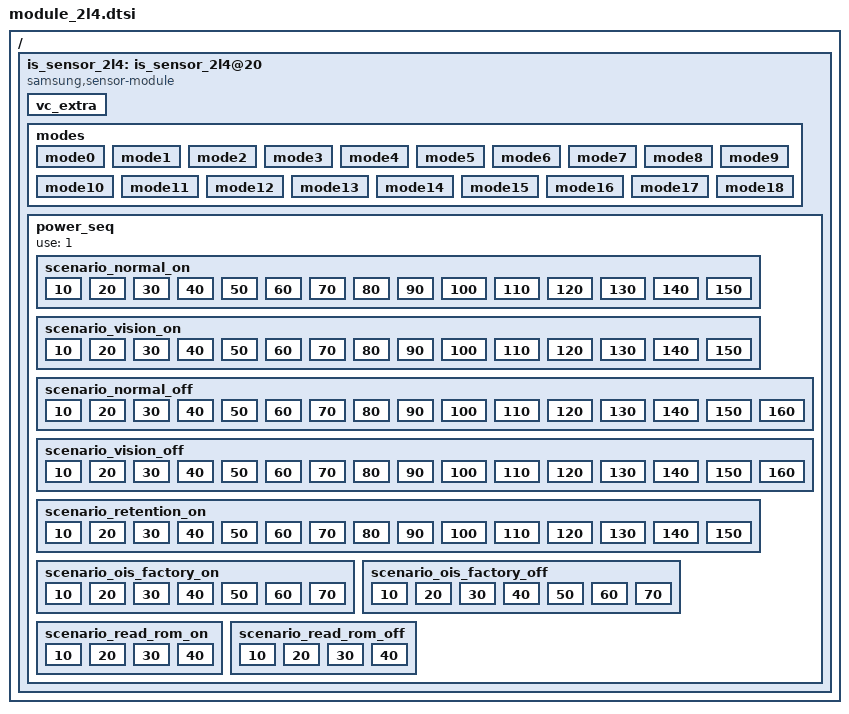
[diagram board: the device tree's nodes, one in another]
/*
 * SAMSUNG EXYNOSxxxx board camera device tree source
 *
 * Copyright (c) 2019 Samsung Electronics Co., Ltd.
 *		http://www.samsung.com
 *
 * This program is free software; you can redistribute it and/or modify
 * it under the terms of the GNU General Public License version 2 as
 * published by the Free Software Foundation.
 */

#include <dt-bindings/camera/exynos_is_dt.h>

/ {
	fragment@camera {
		target-path = "/";
		__overlay__ {
			is_sensor_2l4: is_sensor_2l4@20 {
				compatible = "samsung,sensor-module";

				/* common */
				sensor_id = <SENSOR_NAME_SAK2L4>;
				active_width = <4032>;
				active_height = <3024>;
				margin_left = <0>;
				margin_right = <0>;
				margin_top = <0>;
				margin_bottom = <0>;
				max_framerate = <480>;
				bitwidth = <10>;
				use_retention_mode = <SENSOR_RETENTION_INACTIVE>;
				sensor_maker = "SLSI";
				sensor_name = "SAK2L4";
				setfile_name = "setfile_2l4.bin";

				status = "okay";

				vc_extra {
					/* ex) statX = <stat_type, sensor_mode, max_width, max_height, max_element> */
					stat0 = </* not avaliable */>;									/* VC_BUF_DATA_TYPE_SENSOR_STAT1 */
					stat1 = </*VC_STAT_TYPE_PDP_1_1_PDAF_STAT0*/ 500 /*VC_SENSOR_MODE_2PD_MODE3*/ 102 1756 1 1>;	/* VC_BUF_DATA_TYPE_GENERAL_STAT1 */
					stat2 = </* not avaliable */>;									/* VC_BUF_DATA_TYPE_SENSOR_STAT2 */
					stat3 = </*VC_STAT_TYPE_PDP_1_1_PDAF_STAT1*/ 501 /*VC_SENSOR_MODE_2PD_MODE3*/ 102 39424 1 1>;	/* VC_BUF_DATA_TYPE_GENERAL_STAT2 */
				};

				/* sensor modes */
				modes {
						/* common = <width, height, fps, settle, mode, lane, speed, interleave, lrte, pd_mode> */
						/* vcX = <map, hwformat, width, height, hwformat, type, width, height> */
					mode0 {
						common = <4032 3024 30 0 0 CSI_DATA_LANES_4 2054 CSI_MODE_VC_ONLY LRTE_DISABLE PD_MOD3 EX_NONE>;
						vc0 = </* in */ 0 HW_FORMAT_RAW10 4032 3024	/* out */ HW_FORMAT_RAW10 VC_NOTHING 4032 3024>;
						vc1 = </* in */ 1 HW_FORMAT_RAW10 4032 756	/* out */ HW_FORMAT_RAW10 VC_NOTHING 0 0>;
						vc2 = </* in */ 2 HW_FORMAT_UNKNOWN 0 0		/* out */ HW_FORMAT_USER VC_MIPISTAT 39424 1>;
						vc3 = </* in */ 3 HW_FORMAT_UNKNOWN 0 0		/* out */ HW_FORMAT_USER VC_PRIVATE 1756 1>;
					};
					mode1 {
						common = <4032 2268 60 0 1 CSI_DATA_LANES_4 2177 CSI_MODE_VC_ONLY LRTE_DISABLE PD_MOD3 EX_NONE>;
						vc0 = </* in */ 0 HW_FORMAT_RAW10 4032 2268	/* out */ HW_FORMAT_RAW10 VC_NOTHING 4032 2268>;
						vc1 = </* in */ 1 HW_FORMAT_RAW10 4032 566	/* out */ HW_FORMAT_RAW10 VC_NOTHING 0 0>;
						vc2 = </* in */ 2 HW_FORMAT_UNKNOWN 0 0		/* out */ HW_FORMAT_USER VC_MIPISTAT 39424 1>;
						vc3 = </* in */ 3 HW_FORMAT_UNKNOWN 0 0		/* out */ HW_FORMAT_USER VC_PRIVATE 1756 1>;
					};
					mode2 {
						common = <4032 2268 30 0 2 CSI_DATA_LANES_4 2054 CSI_MODE_VC_ONLY LRTE_DISABLE PD_MOD3 EX_NONE>;
						vc0 = </* in */ 0 HW_FORMAT_RAW10 4032 2268	/* out */ HW_FORMAT_RAW10 VC_NOTHING 4032 2268>;
						vc1 = </* in */ 1 HW_FORMAT_RAW10 4032 566	/* out */ HW_FORMAT_RAW10 VC_NOTHING 0 0>;
						vc2 = </* in */ 2 HW_FORMAT_UNKNOWN 0 0		/* out */ HW_FORMAT_USER VC_MIPISTAT 39424 1>;
						vc3 = </* in */ 3 HW_FORMAT_UNKNOWN 0 0		/* out */ HW_FORMAT_USER VC_PRIVATE 1756 1>;
					};
					mode3 {
						common = <4032 1908 30 0 3 CSI_DATA_LANES_4 2054 CSI_MODE_VC_ONLY LRTE_DISABLE PD_MOD3 EX_NONE>;
						vc0 = </* in */ 0 HW_FORMAT_RAW10 4032 1908	/* out */ HW_FORMAT_RAW10 VC_NOTHING 4032 1908>;
						vc1 = </* in */ 1 HW_FORMAT_RAW10 4032 476	/* out */ HW_FORMAT_RAW10 VC_NOTHING 0 0>;
						vc2 = </* in */ 2 HW_FORMAT_UNKNOWN 0 0		/* out */ HW_FORMAT_USER VC_MIPISTAT 39424 1>;
						vc3 = </* in */ 3 HW_FORMAT_UNKNOWN 0 0		/* out */ HW_FORMAT_USER VC_PRIVATE 1756 1>;
					};
					mode4 {
						common = <3024 3024 30 0 4 CSI_DATA_LANES_4 2054 CSI_MODE_VC_ONLY LRTE_DISABLE PD_MOD3 EX_NONE>;
						vc0 = </* in */ 0 HW_FORMAT_RAW10 3024 3024	/* out */ HW_FORMAT_RAW10 VC_NOTHING 3024 3024>;
						vc1 = </* in */ 1 HW_FORMAT_RAW10 3024 756	/* out */ HW_FORMAT_RAW10 VC_NOTHING 0 0>;
						vc2 = </* in */ 2 HW_FORMAT_UNKNOWN 0 0		/* out */ HW_FORMAT_USER VC_MIPISTAT 39424 1>;
						vc3 = </* in */ 3 HW_FORMAT_UNKNOWN 0 0		/* out */ HW_FORMAT_USER VC_PRIVATE 1756 1>;
					};
					mode5 {
						common = <2016 1512 30 0 5 CSI_DATA_LANES_4 1352 CSI_MODE_VC_ONLY LRTE_DISABLE PD_MOD3 EX_NONE>;
						vc0 = </* in */ 0 HW_FORMAT_RAW10 2016 1512	/* out */ HW_FORMAT_RAW10 VC_NOTHING 2016 1512>;
						vc1 = </* in */ 1 HW_FORMAT_RAW10 2016 378	/* out */ HW_FORMAT_UNKNOWN VC_NOTHING 0 0>;
						vc2 = </* in */ 2 HW_FORMAT_UNKNOWN 0 0		/* out */ HW_FORMAT_USER VC_MIPISTAT 39424 1>;
						vc3 = </* in */ 3 HW_FORMAT_UNKNOWN 0 0		/* out */ HW_FORMAT_USER VC_PRIVATE 1756 1>;
					};
					mode6 {
						common = <2016 1134 30 0 6 CSI_DATA_LANES_4 1352 CSI_MODE_VC_ONLY LRTE_DISABLE PD_MOD3 EX_NONE>;
						vc0 = </* in */ 0 HW_FORMAT_RAW10 2016 1134	/* out */ HW_FORMAT_RAW10 VC_NOTHING 2016 1134>;
						vc1 = </* in */ 1 HW_FORMAT_RAW10 2016 282	/* out */ HW_FORMAT_UNKNOWN VC_NOTHING 0 0>;
						vc2 = </* in */ 2 HW_FORMAT_UNKNOWN 0 0		/* out */ HW_FORMAT_USER VC_MIPISTAT 39424 1>;
						vc3 = </* in */ 3 HW_FORMAT_UNKNOWN 0 0		/* out */ HW_FORMAT_USER VC_PRIVATE 1756 1>;
					};
					mode7 {
						common = <1504 1504 30 0 7 CSI_DATA_LANES_4 1352 CSI_MODE_VC_ONLY LRTE_DISABLE PD_MOD3 EX_NONE>;
						vc0 = </* in */ 0 HW_FORMAT_RAW10 1504 1504	/* out */ HW_FORMAT_RAW10 VC_NOTHING 1504 1504>;
						vc1 = </* in */ 1 HW_FORMAT_RAW10 1504 376	/* out */ HW_FORMAT_UNKNOWN VC_NOTHING 0 0>;
						vc2 = </* in */ 2 HW_FORMAT_UNKNOWN 0 0		/* out */ HW_FORMAT_USER VC_MIPISTAT 39424 1>;
						vc3 = </* in */ 3 HW_FORMAT_UNKNOWN 0 0		/* out */ HW_FORMAT_USER VC_PRIVATE 1756 1>;
					};
					/* MODE 3 - 24fps LIVE FOCUS */
					mode8 {
						common = <4032 3024 24 0 8 CSI_DATA_LANES_4 2054 CSI_MODE_VC_ONLY LRTE_DISABLE PD_MOD3 EX_LIVEFOCUS>;
						vc0 = </* in */ 0 HW_FORMAT_RAW10 4032 3024	/* out */ HW_FORMAT_RAW10 VC_NOTHING 4032 3024>;
						vc1 = </* in */ 1 HW_FORMAT_RAW10 4032 756	/* out */ HW_FORMAT_RAW10 VC_NOTHING 0 0>;
						vc2 = </* in */ 2 HW_FORMAT_UNKNOWN 0 0		/* out */ HW_FORMAT_USER VC_MIPISTAT 39424 1>;
						vc3 = </* in */ 3 HW_FORMAT_UNKNOWN 0 0		/* out */ HW_FORMAT_USER VC_PRIVATE 1756 1>;
					};
					mode9 {
						common = <4032 2268 24 0 9 CSI_DATA_LANES_4 2054 CSI_MODE_VC_ONLY LRTE_DISABLE PD_MOD3 EX_LIVEFOCUS>;
						vc0 = </* in */ 0 HW_FORMAT_RAW10 4032 2268	/* out */ HW_FORMAT_RAW10 VC_NOTHING 4032 2268>;
						vc1 = </* in */ 1 HW_FORMAT_RAW10 4032 566	/* out */ HW_FORMAT_RAW10 VC_NOTHING 0 0>;
						vc2 = </* in */ 2 HW_FORMAT_UNKNOWN 0 0		/* out */ HW_FORMAT_USER VC_MIPISTAT 39424 1>;
						vc3 = </* in */ 3 HW_FORMAT_UNKNOWN 0 0		/* out */ HW_FORMAT_USER VC_PRIVATE 1756 1>;
					};
					mode10 {
						common = <4032 1908 24 0 10 CSI_DATA_LANES_4 2054 CSI_MODE_VC_ONLY LRTE_DISABLE PD_MOD3 EX_LIVEFOCUS>;
						vc0 = </* in */ 0 HW_FORMAT_RAW10 4032 1908	/* out */ HW_FORMAT_RAW10 VC_NOTHING 4032 1908>;
						vc1 = </* in */ 1 HW_FORMAT_RAW10 4032 476	/* out */ HW_FORMAT_RAW10 VC_NOTHING 0 0>;
						vc2 = </* in */ 2 HW_FORMAT_UNKNOWN 0 0		/* out */ HW_FORMAT_USER VC_MIPISTAT 39424 1>;
						vc3 = </* in */ 3 HW_FORMAT_UNKNOWN 0 0		/* out */ HW_FORMAT_USER VC_PRIVATE 1756 1>;
					};
					mode11 {
						common = <3024 3024 24 0 11 CSI_DATA_LANES_4 2054 CSI_MODE_VC_ONLY LRTE_DISABLE PD_MOD3 EX_LIVEFOCUS>;
						vc0 = </* in */ 0 HW_FORMAT_RAW10 3024 3024	/* out */ HW_FORMAT_RAW10 VC_NOTHING 3024 3024>;
						vc1 = </* in */ 1 HW_FORMAT_RAW10 3024 756	/* out */ HW_FORMAT_RAW10 VC_NOTHING 0 0>;
						vc2 = </* in */ 2 HW_FORMAT_UNKNOWN 0 0		/* out */ HW_FORMAT_USER VC_MIPISTAT 39424 1>;
						vc3 = </* in */ 3 HW_FORMAT_UNKNOWN 0 0		/* out */ HW_FORMAT_USER VC_PRIVATE 1756 1>;
					};
					/* MODE 2 */
					mode12 {
						common = <2016 1134 240 0 12 CSI_DATA_LANES_4 2054 CSI_MODE_VC_ONLY LRTE_DISABLE PD_NONE EX_NONE>;
						vc0 = </* in */ 0 HW_FORMAT_RAW10 2016 1134	/* out */ HW_FORMAT_RAW10 VC_NOTHING 2016 1134>;
						vc1 = </* in */ 0 HW_FORMAT_UNKNOWN 0 0		/* out */ HW_FORMAT_UNKNOWN VC_NOTHING 0 0>;
						vc2 = </* in */ 2 HW_FORMAT_UNKNOWN 0 0		/* out */ HW_FORMAT_UNKNOWN VC_NOTHING 0 0>;
						vc3 = </* in */ 3 HW_FORMAT_UNKNOWN 0 0		/* out */ HW_FORMAT_UNKNOWN VC_NOTHING 0 0>;
					};
					mode13 {
						common = <1008 756 120 0 13 CSI_DATA_LANES_4 2054 CSI_MODE_VC_ONLY LRTE_DISABLE PD_NONE EX_NONE>;
						vc0 = </* in */ 0 HW_FORMAT_RAW10 1008 756	/* out */ HW_FORMAT_RAW10 VC_NOTHING 1008 756>;
						vc1 = </* in */ 0 HW_FORMAT_UNKNOWN 0 0		/* out */ HW_FORMAT_UNKNOWN VC_NOTHING 0 0>;
						vc2 = </* in */ 2 HW_FORMAT_UNKNOWN 0 0		/* out */ HW_FORMAT_UNKNOWN VC_NOTHING 0 0>;
						vc3 = </* in */ 3 HW_FORMAT_UNKNOWN 0 0		/* out */ HW_FORMAT_UNKNOWN VC_NOTHING 0 0>;
					};
					/* MODE 2 - SSM */
					mode14 {
						common = <2016 1134 60 0 14 CSI_DATA_LANES_4 2054 CSI_MODE_VC_DT LRTE_DISABLE PD_NONE EX_DUALFPS_960>;
						vc0 = </* in */ 0 HW_FORMAT_RAW10 2016 1134		/* out */ HW_FORMAT_RAW10 VC_NOTHING 2016 1134>;
						vc1 = </* in */ 1 HW_FORMAT_UNKNOWN 0 0			/* out */ HW_FORMAT_UNKNOWN VC_NOTHING 0 0>;
						vc2 = </* in */ 2 HW_FORMAT_UNKNOWN 0 0			/* out */ HW_FORMAT_UNKNOWN VC_NOTHING 0 0>;
						vc3 = </* in */ 0 HW_FORMAT_EMBEDDED_8BIT 2016 4	/* out */ HW_FORMAT_EMBEDDED_8BIT VC_EMBEDDED 2016 4>;
					};
					mode15 {
						common = <2016 1134 60 0 15 CSI_DATA_LANES_4 2054 CSI_MODE_VC_DT LRTE_DISABLE PD_NONE EX_DUALFPS_480>;
						vc0 = </* in */ 0 HW_FORMAT_RAW10 2016 1134		/* out */ HW_FORMAT_RAW10 VC_NOTHING 2016 1134>;
						vc1 = </* in */ 1 HW_FORMAT_UNKNOWN 0 0			/* out */ HW_FORMAT_UNKNOWN VC_NOTHING 0 0>;
						vc2 = </* in */ 2 HW_FORMAT_UNKNOWN 0 0			/* out */ HW_FORMAT_UNKNOWN VC_NOTHING 0 0>;
						vc3 = </* in */ 0 HW_FORMAT_EMBEDDED_8BIT 2016 4	/* out */ HW_FORMAT_EMBEDDED_8BIT VC_EMBEDDED 2016 4>;
					};
					mode16 {
						common = <1280 720 60 0 16 CSI_DATA_LANES_4 2054 CSI_MODE_VC_DT LRTE_DISABLE PD_NONE EX_DUALFPS_960>;
						vc0 = </* in */ 0 HW_FORMAT_RAW10 1280 720		/* out */ HW_FORMAT_RAW10 VC_NOTHING 1280 720>;
						vc1 = </* in */ 1 HW_FORMAT_UNKNOWN 0 0			/* out */ HW_FORMAT_UNKNOWN VC_NOTHING 0 0>;
						vc2 = </* in */ 2 HW_FORMAT_UNKNOWN 0 0			/* out */ HW_FORMAT_UNKNOWN VC_NOTHING 0 0>;
						vc3 = </* in */ 0 HW_FORMAT_EMBEDDED_8BIT 1280 4	/* out */ HW_FORMAT_EMBEDDED_8BIT VC_EMBEDDED 1280 4>;
					};
					mode17 {
						common = <1280 720 60 0 17 CSI_DATA_LANES_4 2054 CSI_MODE_VC_DT LRTE_DISABLE PD_NONE EX_DUALFPS_480>;
						vc0 = </* in */ 0 HW_FORMAT_RAW10 1280 720		/* out */ HW_FORMAT_RAW10 VC_NOTHING 1280 720>;
						vc1 = </* in */ 1 HW_FORMAT_UNKNOWN 0 0			/* out */ HW_FORMAT_UNKNOWN VC_NOTHING 0 0>;
						vc2 = </* in */ 2 HW_FORMAT_UNKNOWN 0 0			/* out */ HW_FORMAT_UNKNOWN VC_NOTHING 0 0>;
						vc3 = </* in */ 0 HW_FORMAT_EMBEDDED_8BIT 1280 4	/* out */ HW_FORMAT_EMBEDDED_8BIT VC_EMBEDDED 1280 4>;
					};
					/* MODE 2 - FACTORY AEB */
					mode18 {
						common = <4032 3024 30 0 18 CSI_DATA_LANES_4 2054 CSI_MODE_VC_ONLY LRTE_DISABLE PD_NONE EX_DRAMTEST>;
						vc0 = </* in */ 0 HW_FORMAT_RAW10 4032 3024	/* out */ HW_FORMAT_RAW10 VC_NOTHING 4032 3024>;
						vc1 = </* in */ 0 HW_FORMAT_UNKNOWN 0 0		/* out */ HW_FORMAT_UNKNOWN VC_NOTHING 0 0>;
						vc2 = </* in */ 2 HW_FORMAT_UNKNOWN 0 0		/* out */ HW_FORMAT_UNKNOWN VC_NOTHING 0 0>;
						vc3 = </* in */ 3 HW_FORMAT_UNKNOWN 0 0		/* out */ HW_FORMAT_UNKNOWN VC_NOTHING 0 0>;
					};
				};


				power_seq {
					use = <1>;
					scenario_normal_on {
						sensor_scenario = <SENSOR_SCENARIO_NORMAL>;
						gpio_scenario = <GPIO_SCENARIO_ON>;

						/* A start node number should be over the 10 for reserved number 0~9. */
						/* pname = "name"; pin = <act value dealy voltage>; gpio = <gpx# # 0x1>; */
						10 { pname = "sen_rst low"; pin = <PIN_OUTPUT 0 0>; gpio = <&gpg2 6 0x1>; };
						20 { pname = "VDDD_RET_1.0V_CAM"; pin = <PIN_REGULATOR 1 1 1025000>; };
						30 { pname = "VDDA_2.8V_CAM"; pin = <PIN_REGULATOR 1 0>; };
						40 { pname = "VDDA_2.4V_CAM"; pin = <PIN_REGULATOR 1 1>; };
						50 { pname = "VDDD_1.0V_CAM"; pin = <PIN_REGULATOR 1 1>; };
						60 { pname = "VDDAF_COMMON_CAM"; pin = <PIN_REGULATOR 1 1>; };
						70 { pname = "VDDIO_1.8V_CAM"; pin = <PIN_REGULATOR 1 1>; };
						80 { pname = "VDDQ_1.1V_CAM"; pin = <PIN_REGULATOR 1 1000>; };
						90 { pname = "VDD_VM_2.8V_OIS"; pin = <PIN_REGULATOR 1 100>; };
						100 { pname = "VDDD_1.8V_OIS"; pin = <PIN_REGULATOR 1 0>; };
						110 { pname = "on_i2c"; pin = <PIN_I2C 1 0>; };
						120 { pname = "pin"; pin = <PIN_FUNCTION 2 0>; };
						130 { pname = "MCLK"; pin = <PIN_MCLK 1 1500>; };
						140 { pname = "sen_rst high"; pin = <PIN_OUTPUT 1 3000>; gpio = <&gpg2 6 0x1>; };
						150 { pname = "ois_rst high"; pin = <PIN_OUTPUT 1 20000>; gpio = <&gpg0 6 0x1>; };
					};

					scenario_vision_on {
						sensor_scenario = <SENSOR_SCENARIO_VISION>;
						gpio_scenario = <GPIO_SCENARIO_ON>;

						/* A start node number should be over the 10 for reserved number 0~9. */
						/* pname = "name"; pin = <act value dealy voltage>; gpio = <gpx# # 0x1>; */
						10 { pname = "sen_rst low"; pin = <PIN_OUTPUT 0 0>; gpio = <&gpg2 6 0x1>; };
						20 { pname = "VDDD_RET_1.0V_CAM"; pin = <PIN_REGULATOR 1 1 1025000>; };
						30 { pname = "VDDA_2.8V_CAM"; pin = <PIN_REGULATOR 1 0>; };
						40 { pname = "VDDA_2.4V_CAM"; pin = <PIN_REGULATOR 1 1>; };
						50 { pname = "VDDD_1.0V_CAM"; pin = <PIN_REGULATOR 1 1>; };
						60 { pname = "VDDAF_COMMON_CAM"; pin = <PIN_REGULATOR 1 1>; };
						70 { pname = "VDDIO_1.8V_CAM"; pin = <PIN_REGULATOR 1 1>; };
						80 { pname = "VDDQ_1.1V_CAM"; pin = <PIN_REGULATOR 1 1000>; };
						90 { pname = "VDD_VM_2.8V_OIS"; pin = <PIN_REGULATOR 1 100>; };
						100 { pname = "VDDD_1.8V_OIS"; pin = <PIN_REGULATOR 1 0>; };
						110 { pname = "on_i2c"; pin = <PIN_I2C 1 0>; };
						120 { pname = "pin"; pin = <PIN_FUNCTION 2 0>; };
						130 { pname = "MCLK"; pin = <PIN_MCLK 1 1500>; };
						140 { pname = "sen_rst high"; pin = <PIN_OUTPUT 1 3000>; gpio = <&gpg2 6 0x1>; };
						150 { pname = "ois_rst high"; pin = <PIN_OUTPUT 1 20000>; gpio = <&gpg0 6 0x1>; };
					};

					scenario_normal_off {
						sensor_scenario = <SENSOR_SCENARIO_NORMAL>;
						gpio_scenario = <GPIO_SCENARIO_OFF>;

						/* A start node number should be over the 10 for reserved number 0~9. */
						/* pname = "name"; pin = <act value dealy voltage>; gpio = <gpx# # 0x1>; */
						10 { pname = "VDDAF_COMMON_CAM"; pin = <PIN_REGULATOR 0 10>; };
						20 { pname = "VDDQ_1.1V_CAM"; pin = <PIN_REGULATOR 0 1>; };
						30 { pname = "VDDD_1.0V_CAM"; pin = <PIN_REGULATOR 0 10>; };
						40 { pname = "VDDA_2.8V_CAM"; pin = <PIN_REGULATOR 0 0>; };
						50 { pname = "VDDA_2.4V_CAM"; pin = <PIN_REGULATOR 0 0>; };
						60 { pname = "MCLK"; pin = <PIN_MCLK 0 0>; };
						70 { pname = "pin"; pin = <PIN_FUNCTION 0 0>; };
						80 { pname = "pin"; pin = <PIN_FUNCTION 1 0>; };
						90 { pname = "pin"; pin = <PIN_FUNCTION 0 0>; };
						100 { pname = "sen_rst low"; pin = <PIN_OUTPUT 0 10>; gpio = <&gpg2 6 0x1>; };
						110 { pname = "ois_rst low"; pin = <PIN_OUTPUT 0 0>; gpio = <&gpg0 6 0x1>; };
						120 { pname = "off_i2c"; pin = <PIN_I2C 0 0>; };
						130 { pname = "VDDD_1.8V_OIS"; pin = <PIN_REGULATOR 0 0>; };
						140 { pname = "VDD_VM_2.8V_OIS"; pin = <PIN_REGULATOR 0 0>; };
						150 { pname = "VDDD_RET_1.0V_CAM"; pin = <PIN_REGULATOR 0 100>; };
						160 { pname = "VDDIO_1.8V_CAM"; pin = <PIN_REGULATOR 0 10>; };
					};

					scenario_vision_off {
						sensor_scenario = <SENSOR_SCENARIO_VISION>;
						gpio_scenario = <GPIO_SCENARIO_OFF>;

						/* A start node number should be over the 10 for reserved number 0~9. */
						/* pname = "name"; pin = <act value dealy voltage>; gpio = <gpx# # 0x1>; */
						10 { pname = "VDDAF_COMMON_CAM"; pin = <PIN_REGULATOR 0 10>; };
						20 { pname = "VDDQ_1.1V_CAM"; pin = <PIN_REGULATOR 0 1>; };
						30 { pname = "VDDD_1.0V_CAM"; pin = <PIN_REGULATOR 0 10>; };
						40 { pname = "VDDA_2.8V_CAM"; pin = <PIN_REGULATOR 0 0>; };
						50 { pname = "VDDA_2.4V_CAM"; pin = <PIN_REGULATOR 0 0>; };
						60 { pname = "MCLK"; pin = <PIN_MCLK 0 0>; };
						70 { pname = "pin"; pin = <PIN_FUNCTION 0 0>; };
						80 { pname = "pin"; pin = <PIN_FUNCTION 1 0>; };
						90 { pname = "pin"; pin = <PIN_FUNCTION 0 0>; };
						100 { pname = "sen_rst low"; pin = <PIN_OUTPUT 0 10>; gpio = <&gpg2 6 0x1>; };
						110 { pname = "ois_rst low"; pin = <PIN_OUTPUT 0 0>; gpio = <&gpg0 6 0x1>; };
						120 { pname = "off_i2c"; pin = <PIN_I2C 0 0>; };
						130 { pname = "VDDD_1.8V_OIS"; pin = <PIN_REGULATOR 0 0>; };
						140 { pname = "VDD_VM_2.8V_OIS"; pin = <PIN_REGULATOR 0 0>; };
						150 { pname = "VDDD_RET_1.0V_CAM"; pin = <PIN_REGULATOR 0 100>; };
						160 { pname = "VDDIO_1.8V_CAM"; pin = <PIN_REGULATOR 0 10>; };
					};

					scenario_retention_on {
						sensor_scenario = <SENSOR_SCENARIO_NORMAL>;
						gpio_scenario = <GPIO_SCENARIO_SENSOR_RETENTION_ON>;

						/* A start node number should be over the 10 for reserved number 0~9. */
						/* pname = "name"; pin = <act value dealy voltage>; gpio = <gpx# # 0x1>; */
						10 { pname = "(retention) sen_rst low"; pin = <PIN_OUTPUT 0 10>; gpio = <&gpg2 6 0x1>; };
						20 { pname = "MCLK"; pin = <PIN_MCLK 0 0>; };
						30 { pname = "pin"; pin = <PIN_FUNCTION 0 0>; };
						40 { pname = "pin"; pin = <PIN_FUNCTION 1 0>; };
						50 { pname = "pin"; pin = <PIN_FUNCTION 0 0>; };
						60 { pname = "VDDAF_COMMON_CAM"; pin = <PIN_REGULATOR 0 10>; };
						70 { pname = "VDDQ_1.1V_CAM"; pin = <PIN_REGULATOR 0 1>; };
						80 { pname = "VDDD_1.0V_CAM"; pin = <PIN_REGULATOR 0 10>; };
						90 { pname = "VDDA_2.8V_CAM"; pin = <PIN_REGULATOR 0 0>; };
						100 { pname = "VDDA_2.4V_CAM"; pin = <PIN_REGULATOR 0 0>; };
						110 { pname = "ois_rst low"; pin = <PIN_OUTPUT 0 0>;  gpio = <&gpg0 6 0x1>; };
						120 { pname = "off_i2c"; pin = <PIN_I2C 0 0>; };
						130 { pname = "VDD_VM_2.8V_OIS"; pin = <PIN_REGULATOR 0 0>; };
						140 { pname = "VDDD_1.8V_OIS"; pin = <PIN_REGULATOR 0 0>; };
						150 { pname = "VDDD_RET_1.0V_CAM"; pin = <PIN_REGULATOR 1 100 700000>; };
					};

					scenario_ois_factory_on {
						sensor_scenario = <SENSOR_SCENARIO_OIS_FACTORY>;
						gpio_scenario = <GPIO_SCENARIO_ON>;

						/* A start node number should be over the 10 for reserved number 0~9. */
						/* pname = "name"; pin = <act value dealy voltage>; gpio = <gpx# # 0x1>; */
						10 { pname = "VDDAF_COMMON_CAM"; pin = <PIN_REGULATOR 1 0>; };
						20 { pname = "VDDAF_2.8V_SUB"; pin = <PIN_REGULATOR 1 20000>; }; /* CAMERA_REAR2_AF */
						30 { pname = "VDDIO_1.8V_SUB"; pin = <PIN_REGULATOR 1 0>; }; /* CAMERA_REAR2_AF */
						40 { pname = "VDD_VM_2.8V_OIS"; pin = <PIN_REGULATOR 1 0>; };
						50 { pname = "VDDD_1.8V_OIS"; pin = <PIN_REGULATOR 1 0>; };
						60 { pname = "on_i2c"; pin = <PIN_I2C 1 10>; };
						70 { panme = "ois_rst high"; pin = <PIN_OUTPUT 1 10000>;  gpio = <&gpg0 6 0x1>; };
					};

					scenario_ois_factory_off {
						sensor_scenario = <SENSOR_SCENARIO_OIS_FACTORY>;
						gpio_scenario = <GPIO_SCENARIO_OFF>;

						/* A start node number should be over the 10 for reserved number 0~9. */
						/* pname = "name"; pin = <act value dealy voltage>; gpio = <gpx# # 0x1>; */
						10 { pname = "ois_rst low"; pin = <PIN_OUTPUT 0 0>; gpio = <&gpg0 6 0x1>; };
						20 { pname = "off_i2c"; pin = <PIN_I2C 0 0>; };
						30 { pname = "VDD_VM_2.8V_OIS"; pin = <PIN_REGULATOR 0 0>; };
						40 { pname = "VDDD_1.8V_OIS"; pin = <PIN_REGULATOR 0 0>; };
						50 { pname = "VDDAF_COMMON_CAM"; pin = <PIN_REGULATOR 0 0>; };
						60 { pname = "VDDAF_2.8V_SUB"; pin = <PIN_REGULATOR 0 0>; }; /* CAMERA_REAR2_AF */
						70 { pname = "VDDIO_1.8V_SUB"; pin = <PIN_REGULATOR 0 0>; }; /* CAMERA_REAR2_AF */
					};

					scenario_read_rom_on {
						sensor_scenario = <SENSOR_SCENARIO_READ_ROM>;
						gpio_scenario = <GPIO_SCENARIO_ON>;

						/* A start node number should be over the 10 for reserved number 0~9. */
						/* pname = "name"; pin = <act value dealy voltage>; gpio = <gpx# # 0x1>; */
						10 { pname = "VDDD_1.8V_OIS"; pin = <PIN_REGULATOR 1 0>; };
						20 { pname = "VDDIO_1.8V_SUB"; pin = <PIN_REGULATOR 1 1000>; };
						30 { pname = "VDDIO_1.8V_CAM"; pin = <PIN_REGULATOR 1 1000>; };
						40 { pname = "on_i2c"; pin = <PIN_I2C 1 0>; };
					};

					scenario_read_rom_off {
						sensor_scenario = <SENSOR_SCENARIO_READ_ROM>;
						gpio_scenario = <GPIO_SCENARIO_OFF>;

						/* A start node number should be over the 10 for reserved number 0~9. */
						/* pname = "name"; pin = <act value dealy voltage>; gpio = <gpx# # 0x1>; */
						10 { pname = "VDDD_1.8V_OIS"; pin = <PIN_REGULATOR 0 0>; };
						20 { pname = "VDDIO_1.8V_SUB"; pin = <PIN_REGULATOR 0 1000>; };
						30 { pname = "off_i2c"; pin = <PIN_I2C 0 0>; };
						40 { pname = "VDDIO_1.8V_CAM"; pin = <PIN_REGULATOR 0 10>; };
					};
				};
			};
		}; /* end of __overlay__ */
	}; /* end of fragment */
}; /* end of root */
